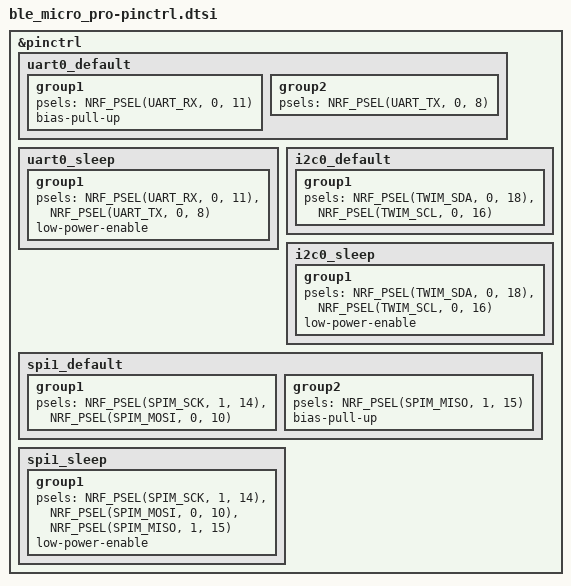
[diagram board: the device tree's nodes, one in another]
/*
 * Copyright (c) 2024 The ZMK Contributors
 * SPDX-License-Identifier: MIT
 */

&pinctrl {
    uart0_default: uart0_default {
        group1 {
            psels = <NRF_PSEL(UART_RX, 0, 11)>;
            bias-pull-up;
        };
        group2 {
            psels = <NRF_PSEL(UART_TX, 0, 8)>;
        };
    };

    uart0_sleep: uart0_sleep {
        group1 {
            psels = <NRF_PSEL(UART_RX, 0, 11)>,
                    <NRF_PSEL(UART_TX, 0, 8)>;
            low-power-enable;
        };
    };

    i2c0_default: i2c0_default {
        group1 {
            psels = <NRF_PSEL(TWIM_SDA, 0, 18)>,
                    <NRF_PSEL(TWIM_SCL, 0, 16)>;
        };
    };

    i2c0_sleep: i2c0_sleep {
        group1 {
            psels = <NRF_PSEL(TWIM_SDA, 0, 18)>,
                    <NRF_PSEL(TWIM_SCL, 0, 16)>;
            low-power-enable;
        };
    };

    spi1_default: spi1_default {
        group1 {
            psels = <NRF_PSEL(SPIM_SCK, 1, 14)>,
                    <NRF_PSEL(SPIM_MOSI, 0, 10)>;
        };
        group2 {
            psels = <NRF_PSEL(SPIM_MISO, 1, 15)>;
            bias-pull-up;
        };
    };

    spi1_sleep: spi1_sleep {
        group1 {
            psels = <NRF_PSEL(SPIM_SCK, 1, 14)>,
                    <NRF_PSEL(SPIM_MOSI, 0, 10)>,
                    <NRF_PSEL(SPIM_MISO, 1, 15)>;
            low-power-enable;
        };
    };
};
